# ICONT1_DM_ICONT register map
Vendor: Texas Instruments
Peripheral module from a debugger description file (folder DRA74xP_75xP_76xP_77xP).
Registers are 32-bit, access per field, reset 0x0 unless marked. A register's access mark holds for its fields unless they carry their own. Offsets are as the file gives them; lines under a group give offsets from that group; [hi:lo] are bit positions; {n}, {i} and the like mark numbered series; 'fields as' and 'values as' point back to an identical list; <NAME> marks a mode.

## ICONT1_DM_ICONT
0x20 ICONT_DM_IRQ_EOI — End Of Interrupt number specification
  [0] LINE_NUMBER rw — Software End Of Interrupt (EOI) control. Write number of interrupt output.
    0=EOI0 (EOI for DM interrupt output); 0=READ0 (Reads always 0 (no EOI memory))
0x24 ICONT_DM_IRQSTATUS_RAW access not given — Per-event raw interrupt status vector (DM interrupt). Raw status is set even if event is not enabled. Write 1 to set the (raw) status, mostly for debug.
  [3:0] LCHN_0 — Settable raw status for Logical Channel n to 0 (n=NB_DM_LCH-1) For each bit of the bit field: Read 0: No event pending Read 1: Event pending Write 0: No action Write 1: Set event (debug) (access RW W1toSet)
0x28 ICONT_DM_IRQSTATUS access not given — Per-event 'enabled' interrupt status vector (DM interrupt). Enabled status is not set unless event is enabled. Write 1 to clear the status after interrupt has been serviced (raw status gets cleared, that is, even if not enabled).
  [3:0] LCHN_0 — Clearable, enabled status for Logical Channel n to 0 (n=NB_DM_LCH-1) For each bit of the bit field: Read 0: No (enabled) event pending Read 1: Event pending Write 0: No action Write 1: Clear (raw) event (access RW W1toClr)
0x2C ICONT_DM_IRQENABLE_SET access not given — Per-event interrupt enable bit vector (DM interrupt). Write 1 to set (enable interrupt). Readout equal to corresponding _CLR register.
  [3:0] LCHN_0 — Enable for Logical Channel n to 0 (n=NB_DM_LCH-1) For each bit of the bit field: Read 0: Interrupt disabled (masked) Read 1: Interrupt enabled Write 0: No action Write 1: Enable interrupt (access RW W1toSet)
0x30 ICONT_DM_IRQENABLE_CLR access not given — Per-event interrupt enable bit vector (DM interrupt). Write 1 to clear (disable interrupt). Readout equal to corresponding _SET register.
  [3:0] LCHN_0 — Enable for Logical Channel n to 0 (n=NB_DM_LCH-1) For each bit of the bitfiled: Read 0: Interrupt disabled (masked) Read 1: Interrupt enabled Write 0: No action Write 1: Disable interrupt (access RW W1toClr)
{0x40+0x20*i} ICONT_DMSOURCEADD_i_{i} (i=0..3) — Data mover source address for context n (Byte address, must be aligned on 128-bit boundary)
  [17:0] SOURCEADDR rw — Source address of transfer
{0x44+0x20*i} ICONT_DMDESTADD_i_{i} (i=0..3) — Data mover destination address for context n (byte address, must be aligned on 128-bit boundary)
  [17:0] DESTADDR rw — Destination address of transfer
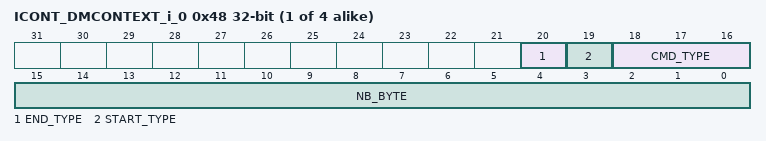
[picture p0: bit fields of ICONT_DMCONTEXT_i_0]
{0x48+0x20*i} ICONT_DMCONTEXT_i_{i} (i=0..3) — Data Mover Context n. A new DM transfer can be scheduled only if this register has been writen by SW.
  [20] END_TYPE rw — 1: Send End Of Logical channel notification on transfer completion 0: Do not send End Of Task notification on transfer completion
  [19] START_TYPE rw — 1: Transfer is scheduled on logical channel start notification 0: Transfer is scheduled on write to ICONT_DMCONTEXT register
  [18:16] CMD_TYPE rw — Type of transfer
    0=Transfer_from_SL2_to_DTCM; 1=Transfer_from_SL2_to_ITCM; 2=DTCM_DMA_IVA_2 (Transfer from DTCM to transversal port of DMA_IVA); 3=SL2_DMA_IVA_3 (Transfer from SL2 to Transversal port of DMA_IVA); 4=Transfer_from_DTCM_to_SL2
  [15:0] NB_BYTE rw — Number of bytes to transfer (must be a multiple of 128b)
{0x4C+0x20*i} ICONT_DMSTATUS_i_{i} ro (i=0..3) — Data Mover status register for context n.
  [1:0] STATUS — 00: LCHn is in IDLE state. Descriptor is free to be programmed (or transfer completed). 01: LCHn is in WAIT FOR HW EVENT state. Descriptor is programmed and is waiting for a hardware event in order to be queued. 10 : LCHn is in either QUEUED state, in ON GOING state, or in COMPLETED state. 11 : Reserved.
